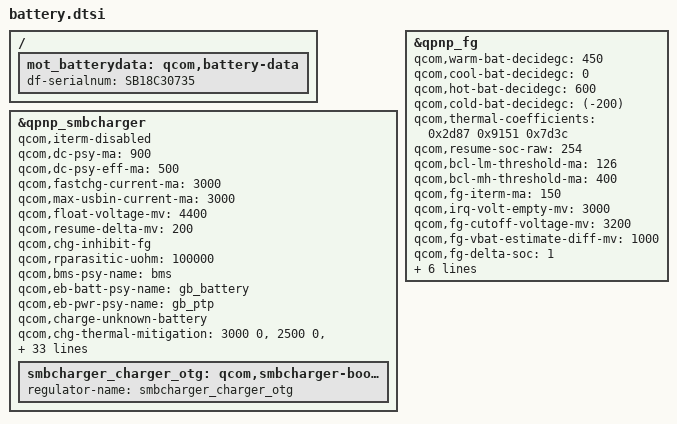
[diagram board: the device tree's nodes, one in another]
/{
	mot_batterydata: qcom,battery-data {
		qcom,batt-id-range-pct = <100>;
		df-serialnum = "SNN5975";
	};
};

&qpnp_smbcharger {
	status = "okay";
	/delete-property/ qcom,iterm-ma;
	qcom,iterm-disabled;
	/delete-property/ qcom,autoadjust-vfloat;
	/delete-property/ qcom,dc-psy-type;
	qcom,dc-psy-ma = <900>;
	qcom,dc-psy-eff-ma = <500>;
	qcom,fastchg-current-ma = <3000>;
	qcom,max-usbin-current-ma = <2600>;
	qcom,float-voltage-mv = <4400>;
	qcom,resume-delta-mv = <200>;
	qcom,chg-inhibit-fg;
	qcom,rparasitic-uohm = <100000>;
	qcom,bms-psy-name = "bms";
	qcom,eb-batt-psy-name = "gb_battery";
	qcom,eb-pwr-psy-name = "gb_ptp";
	qcom,charge-unknown-battery;
	qcom,chg-thermal-mitigation = <3000 0>,
				      <2500 0>,
				      <2000 0>,
				      <1500 0>,
				      <1000 0>,
				      <500 0>;
	qcom,dc-thermal-mitigation = <2000>,
				     <1500>,
				     <900>,
				     <600>,
				     <300>;
	qcom,thermal-mitigation = <3000 0>,
				  <2500 0>,
				  <2000 0>,
				  <1500 0>,
				  <1000 0>,
				  <500 0>,
				  <300 0>;
	qcom,step-chg-steps = <4200 3000 2400>,
				<4400 2400 2000>;
	qcom,stepchg-iterm-ma = <170>;
	qcom,hot-temp-c = <60>;
	qcom,cold-temp-c = <(-20)>;
	qcom,warm-temp-c = <45>;
	qcom,cool-temp-c = <0>;
	qcom,ext-temp-volt-mv = <4200>;
	qcom,external-typec;
	qcom,typec-psy-name = "typec";
	qcom,hotspot-thrs-c = <50>;
	qcom,charging-timeout-mins = <0>;
	qcom,precharging-timeout-mins = <0>;
	qcom,bmd-algo-disabled;
	qcom,bmd-pin-src = "bpd_none";
	qcom,usbid-disabled;
	qcom,force-aicl-rerun;
	mmi,fake-factory-type;
	qcom,auto-voltage-comp-mv = <75>;
	qcom,usbin-vadc = <&pmi8950_vadc>;
	qcom,dcin-vadc = <&pmi8950_vadc>;

};

&qpnp_fg {
	status = "okay";
	qcom,warm-bat-decidegc = <450>;
	qcom,cool-bat-decidegc = <0>;
	qcom,hot-bat-decidegc = <600>;
	qcom,cold-bat-decidegc = <(-200)>;
	qcom,thermal-coefficients =  /bits/ 16 <0x6986 0x5D4B 0x6235>;
	qcom,resume-soc-raw = <254>;
	qcom,bcl-lm-threshold-ma = <126>;
	qcom,bcl-mh-threshold-ma = <400>;
	qcom,fg-iterm-ma = <150>;
	qcom,irq-volt-empty-mv = <2750>;
	qcom,fg-cutoff-voltage-mv = <3000>;
	qcom,fg-vbat-estimate-diff-mv = <1000>;
	qcom,fg-delta-soc = <1>;
	qcom,fg-max-soc = <100>;
	qcom,fg-min-soc = <0>;
	qcom,fg-cc-cv-threshold-mv = <4390>;
	/delete-property/ qcom,capacity-learning-feedback;
	qcom,battery-data = <&mot_batterydata>;
};

/{
	/delete-node/ qcom,battery-data;
	mot_batterydata: qcom,battery-data {
		df-serialnum = "SB18C30735";
		#include "batterydata/batterydata-je40-scud.dtsi"
		#include "batterydata/batterydata-je40-atl.dtsi"
	};
};

&qpnp_smbcharger {
	/delete-property/ pinctrl-names;
	/delete-property/ pinctrl-0;
	/delete-property/ gpios;
	/delete-property/ gpio-names;

	qcom,max-usbin-current-ma = <3000>;
	qcom,step-chg-steps = <4200 3000 2000>,
				<4400 2000 1600>;
	qcom,mmi-temp-zones = <0 582 0>,
				<10 1460 582>,
				<15 1460 1460>,
				<45 3000 2000>,
				<60 1460 0>;
	qcom,auto-voltage-comp-mv = <150>;
	qcom,prop-flash-active;
	qcom,enable-charging-limit;
	qcom,upper-limit-capacity = <75>;
	qcom,lower-limit-capacity = <60>;
	qcom,pd-charger-force-5v;
	qcom,stepchg-iterm-ma = <146>;

	smbcharger_charger_otg: qcom,smbcharger-boost-otg {
		status = "okay";
		regulator-name = "smbcharger_charger_otg";
	};
};

&qpnp_fg {
	/delete-property/ qcom,battery-data;
	qcom,thermal-coefficients =  /bits/ 16 <0x2d87 0x9151 0x7d3c>;
	qcom,irq-volt-empty-mv = <3000>;
	qcom,fg-cutoff-voltage-mv = <3200>;
	qcom,battery-data = <&mot_batterydata>;
	qcom,cl-vbat-est-thr-uv = <300000>;
	qcom,fg-force-restart-enable;
};
